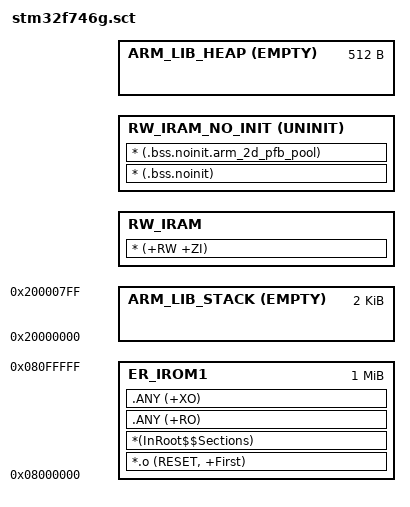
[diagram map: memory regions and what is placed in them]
; *************************************************************
; *** Scatter-Loading Description File generated by uVision ***
; *************************************************************

LR_IROM1 0x08000000 0x00100000  {    ; load region size_region
    ER_IROM1 0x08000000 0x00100000  {  ; load address = execution address
        *.o (RESET, +First)
        *(InRoot$$Sections)
        .ANY (+RO)
        .ANY (+XO)
    }
    
    
    ARM_LIB_STACK 0x20000000 ALIGN 8 EMPTY 0x00000800 {
    }
    
    RW_IRAM +0 {
        * (+RW +ZI)
    }
    
    RW_IRAM_NO_INIT +0 UNINIT  {
        * (.bss.noinit)
        * (.bss.noinit.arm_2d_pfb_pool)
    }

    ARM_LIB_HEAP  +0 ALIGN 8 EMPTY 0x00000200 {
    }
    
}

